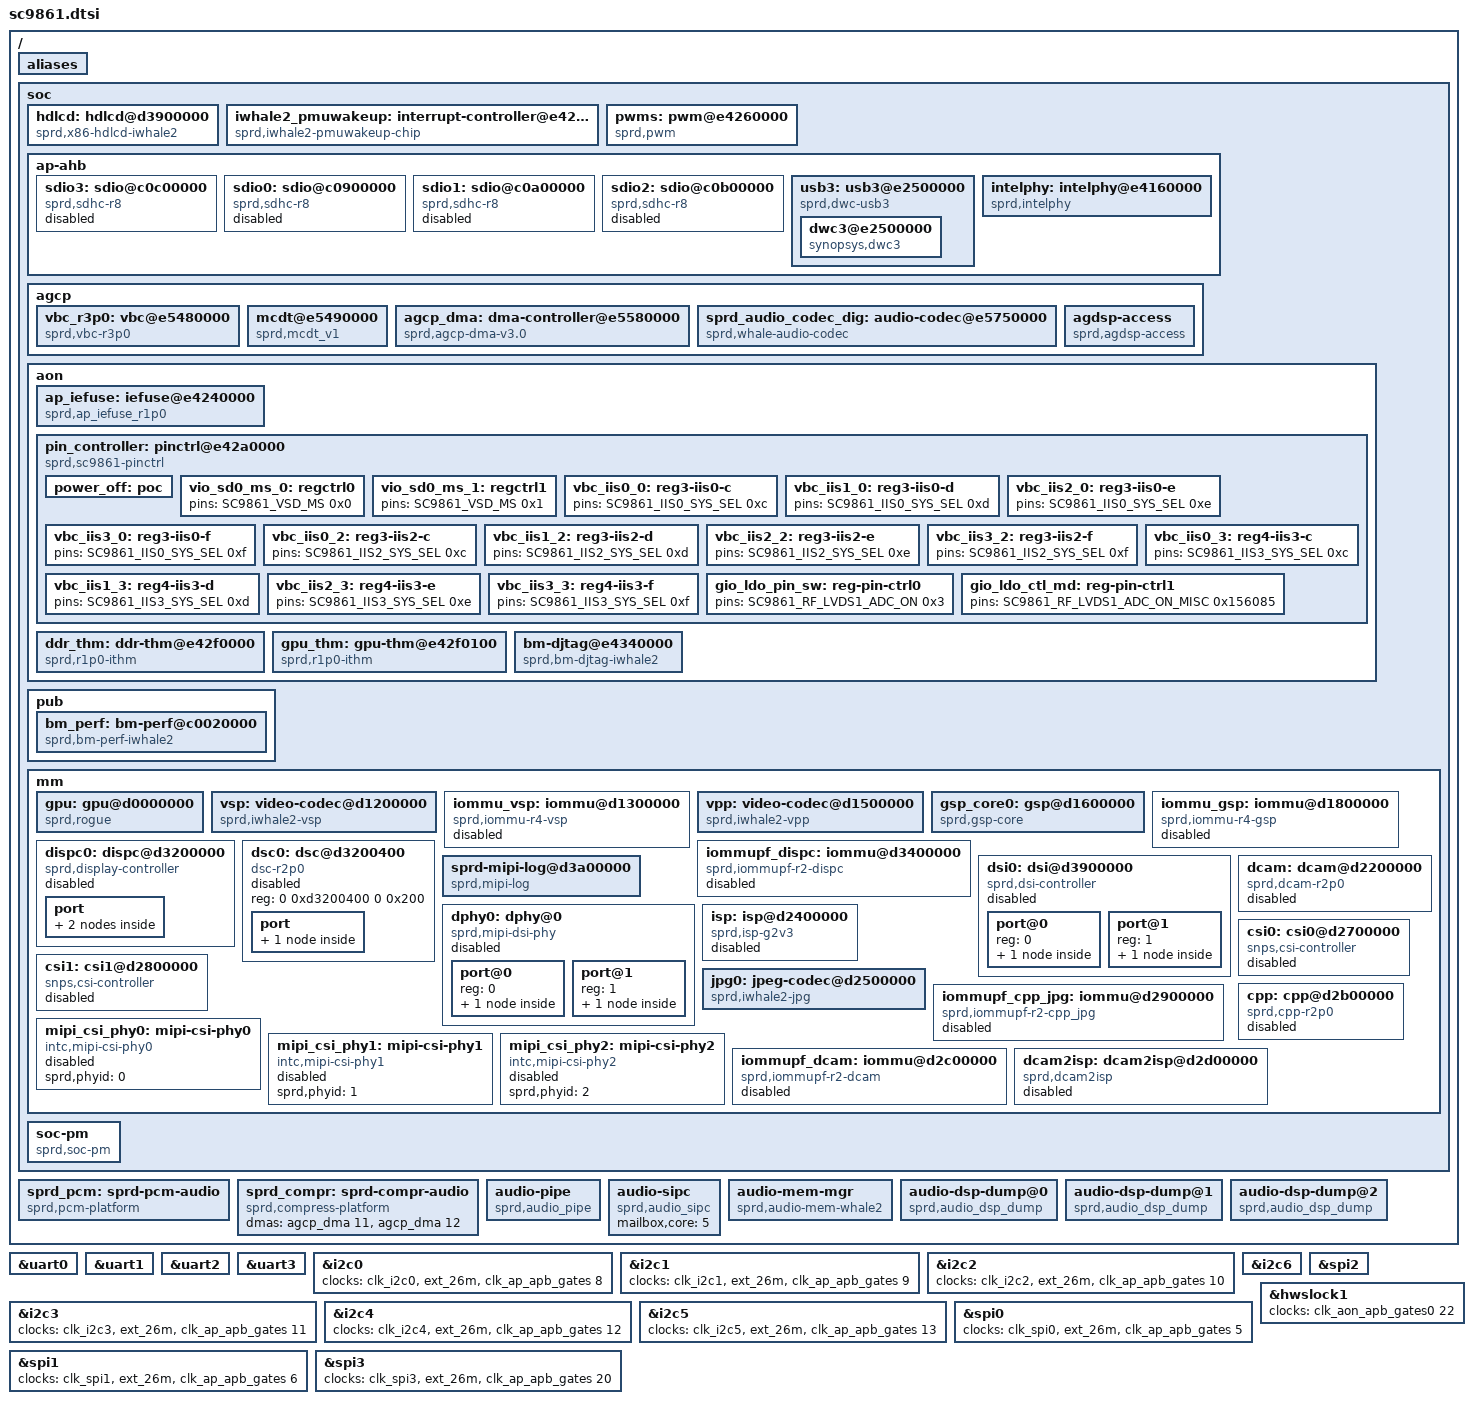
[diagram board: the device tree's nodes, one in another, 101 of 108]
/*
 * Spreadtrum iwhale2 SoC DTS file
 *
 * Copyright (C) 2015, Spreadtrum Communications Inc.
 *
 * This file is licensed under a dual GPLv2 or X11 license.
 */

#include <dt-bindings/pinctrl/sc9861_pinctrl.h>
#include "iwhale2.dtsi"
#include "sc9861-clocks.dtsi"

/{
	aliases {
		thm-sensor1 = &ddr_thm;
		thm-sensor2 = &gpu_thm;
	};

	soc {
		hdlcd:hdlcd@d3900000 {
			compatible = "sprd,x86-hdlcd-iwhale2";
			/* use dispc0 of iwhale2 */
			reg = <0x0 0xd3900000 0x0 0x1000>;
			interrupts = <DISPC0_IRQ 2>;
			clocks = <&ext_26m>;
			clock-names = "pxlclk";
			memory-region = <&fb_reserved>;
			sprd,syscon-lpc-ahb = <&lpc_ahb_controller>;
			sprd,syscon-dispc-ahb = <&dispc_ahb_controller>;
			sprd,syscon-aon-pwu-apb = <&aon_pwu_apb_controller>;
			sprd,syscon-aon-apb = <&aon_apb_controller>;
			sprd,syscon-ap-apb = <&ap_apb_controller>;
		};

		iwhale2_pmuwakeup: interrupt-controller@e42b0254 {
			compatible = "sprd,iwhale2-pmuwakeup-chip";
			interrupt-controller;
			reg = <0 0xe42b0254 0 0x10>;
		};

		pwms: pwm@e4260000 {
				#pwm-cells = <2>;
				compatible = "sprd,pwm";
				reg = <0 0xe4260000 0 0x10000>;
				clock-names = "sprd_pwm_clk_parent", "clk_pwm";
				clocks = <&ext_26m>, <&clk_pwm0>;
				status = "okay";
		};

		ap-ahb {
			sdio3: sdio@c0c00000 {
				compatible  = "sprd,sdhc-r8";
				reg = <0 0xc0c00000 0 0x100000>;
				interrupts = <SDIO3_IRQ 2>;
				clock-names = "sdio","source","enable",
					"ckg_eb","ckg_1x_eb";
				clocks = <&clk_emmc_2x>, <&clk_twpll_384m>,
					<&clk_ap_ahb_gates 10>,
					<&clk_top_cgm_reg1 9>,
					<&clk_top_cgm_reg1 8>;
				status = "disabled";
			};

			sdio0: sdio@c0900000 {
				compatible  = "sprd,sdhc-r8";
				reg = <0 0xc0900000 0 0x100000>;
				interrupts = <SDIO0_IRQ 2>;
				clock-names = "sdio", "source","enable",
					"ckg_eb", "ckg_1x_eb";
				clocks = <&clk_sdio0_2x>, <&clk_twpll_384m>,
					<&clk_ap_ahb_gates 7>,
					<&clk_top_cgm_reg1 2>,
					<&clk_top_cgm_reg1 3>;
				status = "disabled";
			};

			sdio1: sdio@c0a00000 {
				compatible  = "sprd,sdhc-r8";
				reg = <0 0xc0a00000 0 0x100000>;
				interrupts = <SDIO1_IRQ 2>;
				clock-names = "sdio", "source","enable",
					"ckg_eb","ckg_1x_eb";
				clocks = <&clk_sdio1_2x>, <&clk_twpll_384m>,
					<&clk_ap_ahb_gates 8>,
					<&clk_top_cgm_reg1 4>,
					<&clk_top_cgm_reg1 5>;
				status = "disabled";
			};

			sdio2: sdio@c0b00000 {
				compatible  = "sprd,sdhc-r8";
				reg = <0 0xc0b00000 0 0x100000>;
				interrupts = <SDIO2_IRQ 2>;
				clock-names = "sdio", "source","enable",
					"ckg_eb","ckg_1x_eb";
				clocks = <&clk_sdio2_2x>, <&clk_twpll_384m>,
					<&clk_ap_ahb_gates 9>,
					<&clk_top_cgm_reg1 6>,
					<&clk_top_cgm_reg1 7>;
				status = "disabled";
			};

			usb3: usb3@e2500000 {
				compatible = "sprd,dwc-usb3";
				reg = <0 0xe2500000 0 0x100000>;
				#address-cells = <2>;
				#size-cells = <2>;
				ranges;
				sprd,por-after-power-collapse;
				clocks = <&clk_ap_ahb_gates 2>,
					<&clk_ap_ahb_gates 3>,
					<&clk_ap_ahb_gates 4>;
				clock-names = "core_clk", "susp_clk", "ref_clk";
				sprd,syscon-ap-ahb = <&ap_ahb_controller>;

				dwc3@e2500000 {
					compatible = "synopsys,dwc3";
					reg = <0 0xe2500000 0 0xcc00>;
					interrupts = <USB3_IRQ 2>;
					interrupt-names = "irq";
					usb-phy = <&intelphy>, <&intelphy>;
					snps,usb3-u1u2-disable;
					snps,overlap_check_quirk;
					snps,ep_out_aligned_size_quirk;
					snps,disconnect_event_quirk;
				};
			};

			intelphy: intelphy@e4160000 {
				compatible = "sprd,intelphy";
				reg = <0 0xe4160000 0 0x10000>,
					<0 0xe41f0000 0 0x10000>,
					<0 0xe4103000 0 0x40>;
				reg-names = "phy_glb_regs",
						"phy_sideclk_regs",
						"phy_reset_regs";
				sprd,syscon-ap-ahb = <&ap_ahb_controller>;
				sprd,syscon-aon-com-pmu-apb = <&aon_com_pmu_apb_controller>;
				sprd,syscon-anlg-phy-g4 = <&anlg_phy_g4_controller>;
				sprd,vdd-voltage = <3300000>;
			};
		};

		agcp {
			vbc_r3p0: vbc@e5480000 {
				compatible = "sprd,vbc-r3p0";
				#sound-dai-cells = <1>;
				reg = <0 0xe5480000 0 0x1000>;
				mailbox,core = <5>;    /* AGDSP id */
				sprd,syscon-agcp-ahb = <&agcp_ahb_controller>;
				sprd,vbc-phy-offset = <0xe4000000>;
				/* iis pin map */
				pinctrl-names =
				/* iis 0 */
				"vbc_iis0_0", "vbc_iis1_0", "vbc_iis2_0", "vbc_iis3_0",
				/* iis 2 */
				"vbc_iis0_2", "vbc_iis1_2", "vbc_iis2_2", "vbc_iis3_2",
				/* iis 3 */
				"vbc_iis0_3", "vbc_iis1_3", "vbc_iis2_3", "vbc_iis3_3";
				/* sys iis 0 */
				pinctrl-0 = <&vbc_iis0_0>;
				pinctrl-1 = <&vbc_iis1_0>;
				pinctrl-2 = <&vbc_iis2_0>;
				pinctrl-3 = <&vbc_iis3_0>;
				/* sys iis 2 */
				pinctrl-4 = <&vbc_iis0_2>;
				pinctrl-5 = <&vbc_iis1_2>;
				pinctrl-6 = <&vbc_iis2_2>;
				pinctrl-7 = <&vbc_iis3_2>;
				/* sys iis 3 */
				pinctrl-8 = <&vbc_iis0_3>;
				pinctrl-9 = <&vbc_iis1_3>;
				pinctrl-10 = <&vbc_iis2_3>;
				pinctrl-11 = <&vbc_iis3_3>;
				sprd,need-aud-top-clk;
			};

			mcdt@e5490000 {
				compatible = "sprd,mcdt_v1";
				reg = <0 0xe5490000 0 0x170>;
				interrupts = <AGCP_MCDT_IRQ 2>;
				sprd,ap-addr-offset = <0xe4000000>;
			};

			agcp_dma: dma-controller@e5580000 {
				compatible = "sprd,agcp-dma-v3.0";
				reg = <0 0xe5580000 0 0x10000>;
				#dma-cells = <1>;
				#dma-channels = <32>;
				sprd,full-type-offset = <0>;
				sprd,syscon-dma-glb = <&agcp_ahb_controller>;
				clock-names = "enable", "ashb_eb";
				clocks = <&clk_agcp_ahb_gates 6>, <&clk_agcp_ahb_gates 17>;
			};

			sprd_audio_codec_dig: audio-codec@e5750000 {
				compatible = "sprd,whale-audio-codec";
				reg = <0 0xe5750000 0 0x1000>;
				sprd,syscon-agcp-ahb = <&agcp_ahb_controller>;
			};

			agdsp-access {
				compatible = "sprd,agdsp-access";
				sprd,syscon-agcp-ahb = <&aon_apb_controller>;
				sprd,syscon-pmu-apb = <&aon_pwu_apb_controller>;
				sprd,dst = <5>;
				sprd,channel = <130>;
				sprd,sipc-name = "sipc0";
				mailbox,core = <5>; /* AGDSP id */
				sprd,ddr-addr-offset = <0x80000000>;
			};
		};

		aon {
			ap_iefuse: iefuse@e4240000 {
				compatible = "sprd,ap_iefuse_r1p0";
				sprd,syscon-enable = <&aon_apb_controller>;
				reg = <0 0xe4240000 0 0x10000>;
				clock-names = "enable";
				clocks = <&clk_aon_apb_gates0 13>;
				sprd,block-num = <64>;
				sprd,block-width = <32>;
				hwlocks = <&hwslock1 8>;
				hwlock-names = "ap_efuse";
			};

			pin_controller: pinctrl@e42a0000 {
				compatible = "sprd,sc9861-pinctrl";
				reg = <0 0xe42a0000 0 0x10000>;
			};

			ddr_thm: ddr-thm@e42f0000 {
				compatible = "sprd,r1p0-ithm";
				sprd,syscon-enable = <&aon_apb_controller>;
				reg = <0 0xe42f0000 0 0x100>;
				clock-names = "enable";
				clocks = <&clk_aon_apb_gates1 1>;
				#thermal-sensor-cells = <1>;
				power-down = <1>;
				otp-temp = <120000>;
				algor_ver = <0>;
				cal_k = <1455>;
				cal_b = <67200>;
				cal_efuse_blk = <7>;
				cal_efuse_bit = <13>;
				ratio_off_bit = <6>;
				ratio_sign_bit = <12>;
			};

			gpu_thm: gpu-thm@e42f0100 {
				compatible = "sprd,r1p0-ithm";
				sprd,syscon-enable = <&aon_apb_controller>;
				reg = <0 0xe42f0100 0 0x100>;
				clock-names = "enable";
				clocks = <&clk_aon_apb_gates1 1>;
				#thermal-sensor-cells = <1>;
				power-down = <1>;
				otp-temp = <120000>;
				algor_ver = <0>;
				cal_k = <1455>;
				cal_b = <67200>;
				cal_efuse_blk = <8>;
				cal_efuse_bit = <13>;
				ratio_off_bit = <6>;
				ratio_sign_bit = <12>;
			};

			bm-djtag@e4340000 {
				compatible  = "sprd,bm-djtag-iwhale2";
				reg = <0 0xe4340000 0 0x10000>;
				interrupts = <DJTAG_IRQ 2>;
				sprd,syscon-aon-glb = <&aon_apb_controller>;
				sprd,syscon-ap-glb = <&ap_ahb_controller>;
				hwlocks = <&hwslock1 10>;
				hwlock-names = "djtag";
			};
		};

		pub {
			bm_perf: bm-perf@c0020000 {
				compatible = "sprd,bm-perf-iwhale2";
				reg =	<0 0xc0020000 0 0x60000>,
					<0 0xc0820000 0 0x60000>,
					<0 0xe44D0000 0 0x10000>,
					<0 0xc0010000 0 0x4>,
					<0 0xc0810000 0 0x4>;
				reg-names = "pub0","pub1","timer",
						"pub0_glb","pub1_glb";
				interrupts = <PUB0_AXI_BM_IRQ 2>,
						<PUB1_AXI_BM_IRQ 2>;
				sprd,syscon-aon-glb =  <&aon_apb_controller>;
			};
		};

		mm {
			gpu: gpu@d0000000 {
				compatible = "sprd,rogue";
				reg = <0 0xd0000000 0 0x100000>;
				sprd,syscon-aon-pwu-apb = <&aon_pwu_apb_controller>;
				interrupts = <GPU_IRQ 2>;

				clocks = <&clk_aon_apb_gates0 27>,
					<&clk_gpu_core>,<&clk_gpu_mem>,
					<&clk_gpu_sys>,<&clk_twpll_384m>,
					<&clk_twpll_512m>,<&clk_gpll>;

				operating-points = <
					/* kHz    uV */
					384000    840000
					512000    1050000
					583000    1050000
					>;

				sprd,dvfs-lists = <
					/* kHz  uV     idx div */
					384000 840000   4   1
					512000 1050000  5   1
					583000 1050000  6   1
					>;

				sprd,dvfs-default = <2>;
				sprd,dfs-scene-max = <2>;
				sprd,dfs-scene-extreme = <1>;
			};

			vsp: video-codec@d1200000{
				compatible = "sprd,iwhale2-vsp";
				reg = <0 0xd1200000 0 0x20000>;
				interrupts = <VSP_IRQ 2>;
				sprd,syscon-pmu-apb = <&aon_pwu_apb_controller>;
				sprd,syscon-com-pmu-apb = <&aon_com_pmu_apb_controller>;
				sprd,syscon-aon-apb = <&aon_apb_controller>;
				sprd,syscon-mm-ahb = <&vsp_sys_ahb_controller>;
				clock-names = "clk_mm_eb",
						"clk_axi_gate_vsp",
						"clk_vsp_ahb_mmu_eb",
						"clk_vsp_ckg",
						"clk_ahb_gate_vsp_eb",
						"clk_ahb_vsp",
						"ahb_parent_clk",
						"ahb_parent_df_clk",
						"clk_vsp";
				clocks = <&clk_aon_apb_gates1 28>,
					<&clk_vsp_ahb_gates 10>,
					<&clk_vsp_ahb_gates 2>,
					<&clk_vsp_ahb_gates 1>,
					<&clk_vsp_ahb_gates 0>,
					<&clk_vsp_ahb>,
					<&clk_twpll_153m6>,
					<&clk_twpll_96m>,
					<&clk_vsp>;
				iommus = <&iommu_vsp>;
				status = "okay";
			};

			iommu_vsp: iommu@d1300000 {
				compatible = "sprd,iommu-r4-vsp";
				reg = <0 0xd1300000 0 0x20000>,
					<0 0xd1320000 0 0x2000>,
					<0 0xe0000000 0 0x8000000>;
				reg_name = "pgt","ctrl_reg","iova pool";
				clock-names = "clk_vsp_ahb_mmu_eb",
						"clk_vsp_apb_gate";
				clocks = <&clk_vsp_ahb_gates 2>,
						<&clk_aon_apb_gates1 28>;

				sprd,reserved-fault-page = <0xffff0000>;
				sprd,reserved-rr-page = <0x5f700000>;
				page-table-offset = <1>;
				page-table-size = <256>;
				status = "disable";
				#iommu-cells = <0>;
			};

			vpp: video-codec@d1500000{
				compatible = "sprd,iwhale2-vpp";
				reg = <0 0xd1500000 0 0xc000>;
				interrupts = <VPP_DEINT_IRQ 2>;
				sprd,syscon-aon-apb = <&aon_apb_controller>;
				sprd,syscon-mm-ahb = <&vsp_sys_ahb_controller>;
				clock-names = "clk_mm_eb",
					"clk_axi_gate_vsp",
					"clk_vsp_ckg",
					"clk_ahb_gate_vsp_eb",
					"clk_ahb_vsp",
					"clk_vsp";
				clocks = <&clk_aon_apb_gates1 28>,
					<&clk_vsp_ahb_gates 10>,
					<&clk_vsp_ahb_gates 2>,
					<&clk_vsp_ahb_gates 4>,
					<&clk_vsp_ahb>,
					<&clk_vpp>;
				iommus = <&iommu_vsp>;
				status = "okay";
			};

			gsp_core0: gsp@d1600000 {
				compatible = "sprd,gsp-core";
				reg = <0 0xd1600000 0 0x1000>,
					<0 0xd1100000 0 0x1000>,
					<0 0xd1000000 0 0x1000>;
				reg-names = "gsp_ctl_reg_base",
						"vsp_sys_regmap",
						"vsp_clk_regmap";
				core-id = <0>;
				kcfg-num = <16>;
				interrupts = <GSP0_IRQ 2>;
				iommus = <&iommu_gsp>;
				sprd,syscon-pmu-apb = <&aon_pwu_apb_controller>;
				sprd,syscon-aon-apb = <&aon_apb_controller>;

				clock-names = "clk_gsp0","clk_gsp_parent",
					"clk_gsp_ahb_vsp",
					"clk_gsp_ahb_vsp_parent",
					"clk_gsp_mtx","clk_gsp_mtx_parent",
					"clk_vsys_mtx","clk_vsys_mtx_parent",
					"clk_aon_vsp_eb",
					"clk_gsp_emc_eb",
					"clk_vsp_ahb_ckg_eb",
					"clk_vsys_mtx_eb",
					"clk_gsp0_eb",
					"clk_gsp_mmu_eb",
					"clk_gsp_mtx_eb";
				clocks = <&clk_gsp0>,<&clk_twpll_512m>,
					<&clk_vsp_ahb>,<&clk_twpll_153m6>,
					<&clk_gsp_mtx>,<&clk_twpll_512m>,
					<&clk_vsys_mtx>,<&clk_twpll_512m>,
					<&clk_aon_apb_gates1 28>,
					<&clk_aon_apb_gates1 13>,
					<&clk_vsp_ahb_gates 1>,
					<&clk_vsp_ahb_gates 10>,
					<&clk_vsp_ahb_gates 5>,
					<&clk_vsp_ahb_gates 7>,
					<&clk_vsp_ahb_gates 9>;
			};

			iommu_gsp: iommu@d1800000 {
				compatible = "sprd,iommu-r4-gsp";
				reg = <0 0xd1800000 0 0x40000>,
				<0 0xd1840000 0 0x2000>,
				<0 0xc0000000 0 0xc800000>;
				reg_name = "pgt","ctrl_reg","iova pool";
				clock-names = "clk_dispc_gsp0_mmu_ahb_eb",
						"clk_vsp_eb";
				clocks = <&clk_vsp_ahb_gates 7>,
						<&clk_aon_apb_gates1 28>;
				sprd,reserved-fault-page = <0xffff0000>;
				page-table-offset = <0>;
				page-table-size = <256>;
				status = "disable";
				#iommu-cells = <0>;
			};

			dispc0: dispc@d3200000 {
				compatible = "sprd,display-controller";
				reg = <0 0xd3200000 0 0x1000>;
				dev-id = <0>;
				sprd,dpi_clk_div = <1>;
				interrupts = <DISPC0_IRQ 2>;
				clock-src = <512000000 256000000 256000000>;
				clock-names =   "clk_dispc_core_parent",
						"clk_dispc_dpi_parent",
						"clk_dispc_core",
						"clk_dispc_dpi",
						"clk_dispc_ahb_eb",
						"clk_dispc_mmu_ahb_eb",
						"clk_dispc_ckg_ahb_eb",
						"clk_dispc_mtx_ahb_eb",
						"clk_disp_emc_apb_eb",
						"clk_disp_apb_eb";

				clocks =	<&clk_twpll_512m>,
						<&clk_twpll_256m>,
						<&clk_dispc0>,
						<&clk_dispc0_dpi>,
						<&clk_dahb_gates 0>,
						<&clk_dahb_gates 2>,
						<&clk_dahb_gates 9>,
						<&clk_dahb_gates 16>,
						<&clk_aon_apb_gates1 11>,
						<&clk_aon_apb_gates1 30>;

				status = "disabled";

				sprd,ip = "dispc-r8p0";
				sprd,soc = "iwhale2";

				/* output port */
				port {
					#address-cells = <1>;
					#size-cells = <0>;

					dispc0_out: endpoint@0 {
						reg = <0>;
						remote-endpoint = <&dsi0_in>;
					};

					dispc0_dsc0: endpoint@1 {
						reg = <1>;
						remote-endpoint = <&dsc0_dispc0>;
					};
				};
			};

			dsc0: dsc@d3200400 {
				compatible  = "dsc-r2p0";
				reg = <0 0xd3200400 0 0x200>;
				status = "disable";

				/* input port */
				port {
					dsc0_dispc0: endpoint {
						remote-endpoint = <&dispc0_dsc0>;
					};
				};
			};

			iommupf_dispc: iommu@d3400000 {
				compatible = "sprd,iommupf-r2-dispc";
				reg = <0 0xd3400000 0 0x2000>,
					<0 0xd3402000 0 0x2000>,
					<0 0 0 0>,
					<0 0x30000000 0 0x10000000>;
				reg_name = "pgt",
					"ctrl_reg",
					"iova fullmode pool",
					"iova pf pool";
				clock-names = "clk_dispc_mmu_ahb_eb",
					"clk_dcam_eb";
				clocks = <&clk_dahb_gates 2>,
						<&clk_aon_apb_gates1 29>;
				fullmode-en = <0>;
				total-ch-num = <6>;
				pf-ch-write-start = <0>;
				pf-ch-write-end = <0>;
				pf-ch-read-start = <0>;
				pf-ch-read-end = <5>;
				fullmode-ch-write = <0>;
				fullmode-ch-read = <0>;
				page-table-offset = <4>;
				page-table-size = <100>;
				status = "disable";
				#iommu-cells = <0>;
			};

			dsi0: dsi@d3900000 {
				compatible = "sprd,dsi-controller";
				#address-cells = <1>;
				#size-cells = <0>;
				dev-id = <0>;
				reg = <0 0xd3900000 0 0x1000>;
				interrupts = <DSI0_IRQ 2>;
				clock-names =   "clk_dphy0_ckg_eb",
						"clk_disp_ckg_ahb_eb",
						"clk_dsi0_ahb_eb",
						"clk_disp_apb_eb";

				clocks =	<&clk_dckg_gates 0>,
						<&clk_dahb_gates 9>,
						<&clk_dahb_gates 7>,
						<&clk_aon_apb_gates1 30>;
				status = "disabled";

				sprd,ip = "synps,dwc-mipi-dsi-host";
				sprd,soc = "iwhale2";

				/* output port */
				port@0 {
					reg = <0>;
					dsi0_out: endpoint {
						remote-endpoint = <&dphy0_in>;
					};
				};

				/* input port */
				port@1 {
					reg = <1>;
					dsi0_in: endpoint {
						remote-endpoint = <&dispc0_out>;
					};
				};
			};

			sprd-mipi-log@d3a00000 {
				compatible = "sprd,mipi-log";
				reg = <0 0xd3a00000 0 0x1000>,
				    <0 0x404f0000 0 0x1000>;
				max-lanes = <4>;
				phy-freq = <1000000>;
			};

			dphy0: dphy@0 {
				compatible = "sprd,mipi-dsi-phy";
				#address-cells = <1>;
				#size-cells = <0>;
				reg = <0 0xd3900000 0 0x1000>,
				  <0 0xe41b0000 0 0x1000>;
				status = "disabled";

				sprd,ip = "intel,ip733mdsitop";
				sprd,soc = "iwhale2";

				/* output port */
				port@0 {
					reg = <0>;
					dphy0_out: endpoint {
					};
				};

				/* input port*/
				port@1 {
					reg = <1>;
					dphy0_in: endpoint {
						remote-endpoint = <&dsi0_out>;
					};
				};
			};

			dcam: dcam@d2200000 {
				compatible = "sprd,dcam-r2p0";
				reg = <0 0xd2200000 0 0x100000
					0 0xd2300000 0 0x100000>;
				interrupts = <DCAM0_IRQ 2>,
					<DCAM1_IRQ 2>;
				clock-names = "clk_cam_eb",
					"cam_ckg_eb","cam_mtx_eb",
					"clk_ahb_cam", "clk_ahb_cam_parent",
					"clk_dcam0","clk_dcam0_parent",
					"clk_dcam1","clk_dcam1_parent",
					"clk_dcam0_if","clk_dcam0_if_parent",
					"dcam0_eb","dcam0_axi_eb",
					"dcam1_eb","dcam1_axi_eb",
					"dcam0_if_eb","d0_if_axi_eb",
					"d0if_in_d_eb","d1if_in_d_eb";
				clocks = <&clk_aon_apb_gates1 29>,
					<&clk_dahb_gates 9>,<&clk_cam_ahb_gates 23>,
					<&clk_cam_ahb>,<&clk_twpll_153m6>,
					<&clk_dcam0>,<&clk_twpll_384m>,
					<&clk_dcam1>,<&clk_twpll_384m>,
					<&clk_dcam0_if>,<&clk_twpll_512m>,
					<&clk_cam_ahb_gates 0>,
					<&clk_cam_ckg_gates 4>,
					<&clk_cam_ahb_gates 1>,
					<&clk_cam_ckg_gates 5>,
					<&clk_cam_ahb_gates 20>,
					<&clk_cam_ckg_gates 14>,
					<&clk_module_gates 0>,
					<&clk_module_gates 1>;
				sprd,syscon-cam-ahb = <&lpc_ahb_controller>;
				sprd,syscon-pmu-apb = <&aon_pwu_apb_controller>;
				status = "disable";
			};

			isp: isp@d2400000 {
				compatible = "sprd,isp-g2v3";
				reg = <0 0xd2400000 0 0x100000>;
				interrupts = <ISP_CH0_IRQ 2>;
				clock-names = "clk_isp_mclk","clk_isp_mclk_parent",
					"clk_isp_pclk","clk_isp_pclk_parent",
					"clk_isp_iclk","clk_isp_iclk_parent",
					"clk_isp_lclk","clk_isp_lclk_parent",
					"clk_isp0","clk_isp0_parent",
					"clk_isp1","clk_isp1_parent",
					"clk_isp2","clk_isp2_parent",
					"isp0_eb","isp0_axi_eb",
					"isp1_eb","isp1_axi_eb",
					"isp2_eb","isp2_axi_eb",
					"isp_mclk_eb","isp_pclk_eb",
					"isp_iclk_eb","isp_lclk_eb",
					"isp_i2d_eb","i0_in_isp_eb",
					"i1_in_isp_eb","i2_in_isp_eb";
				clocks = <&clk_isp_mck>,<&clk_twpll_384m>,
					<&clk_isp_pck>,<&clk_twpll_76m8>,
					<&clk_isp_ick>,<&clk_twpll_512m>,
					<&clk_isp_lck>,<&clk_twpll_384m>,
					<&clk_ci_isp0>,<&clk_twpll_512m>,
					<&clk_ci_isp1>,<&clk_twpll_512m>,
					<&clk_ci_isp2>,<&clk_twpll_384m>,
					<&clk_cam_ahb_gates 2>,
					<&clk_cam_ckg_gates 10>,
					<&clk_cam_ahb_gates 9>,
					<&clk_cam_ckg_gates 11>,
					<&clk_cam_ahb_gates 12>,
					<&clk_cam_ckg_gates 12>,
					<&clk_cam_ahb_gates 17>,
					<&clk_cam_ahb_gates 18>,
					<&clk_cam_ahb_gates 16>,
					<&clk_cam_ahb_gates 15>,
					<&clk_cam_ahb_gates 19>,
					<&clk_module_gates 7>,
					<&clk_module_gates 8>,
					<&clk_module_gates 9>;
				sprd,syscon-cam-ahb = <&lpc_ahb_controller>;
				status = "disable";
			};

			jpg0: jpeg-codec@d2500000{
				compatible = "sprd,iwhale2-jpg";
				reg = <0 0xd2500000 0 0x100000>;
				interrupts = <JPG0_IRQ 2>;
				sprd,syscon-aon-apb = <&aon_apb_controller>;
				sprd,syscon-mm-ahb = <&lpc_ahb_controller>;
				clock-names = "clk_mm_eb",
					"clk_axi_gate_jpg",
					"clk_ahb_gate_jpg_eb",
					"clk_ahb_cam",
					"clk_jpg";
				clocks = <&clk_aon_apb_gates1 29>,
					<&clk_cam_ckg_gates 8>,
					<&clk_cam_ahb_gates 5>,
					<&clk_cam_ahb>,
					<&clk_jpg0>;
				/*iommus = <&iommupf_cpp_jpg>;*/
				status = "okay";
			};

			csi0: csi0@d2700000 {
				compatible = "snps,csi-controller";
				reg = <0 0xd2700000 0 0x100000>;
				interrupts = <CSI0_IRQ 2>;
				clock-names = "clk_cphy_gate","clk_mipi_gate",
					"clk_csi_eb","clk_mipi_csi_eb";
				clocks = <&clk_cam_ckg_gates 0>,<&clk_cam_ckg_gates 1>,
					   <&clk_cam_ahb_gates 3>,<&clk_mipi_csi0_gate 16>;
				sprd,ip-version = <0x3131312a>;
				sprd,cam-ahb-syscon = <&lpc_ahb_controller>;
				sprd,aon-apb-syscon = <&aon_apb_controller>;
				sprd,anlg-phy-g8-syscon = <&anlg_phy_g8_controller>;
				status = "disable";
			};

			csi1: csi1@d2800000 {
				compatible = "snps,csi-controller";
				reg = <0 0xd2800000 0 0x100000>;
				interrupts = <CSI1_IRQ 2>;
				clock-names = "clk_cphy_gate","clk_mipi_gate",
					"clk_csi_eb","clk_mipi_csi_eb";
				clocks = <&clk_cam_ckg_gates 2>,<&clk_cam_ckg_gates 3>,
					   <&clk_cam_ahb_gates 4>,<&clk_mipi_csi1_gate 16>;
				sprd,ip-version = <0x3131312a>;
				sprd,cam-ahb-syscon = <&lpc_ahb_controller>;
				sprd,aon-apb-syscon = <&aon_apb_controller>;
				sprd,anlg-phy-g8-syscon = <&anlg_phy_g8_controller>;
				status = "disable";
			};

			iommupf_cpp_jpg: iommu@d2900000 {
				compatible = "sprd,iommupf-r2-cpp_jpg";
				reg = <0 0xd2900000 0 0x2000>,
					<0 0xd2902000 0 0x2000>,
					<0 0x40000000 0 0x8000000>,
					<0 0x50000000 0 0x20000000>;
				reg_name = "pgt",
					"ctrl_reg",
					"iova fullmode pool",
					"iova pf pool";
				clock-names = "clk_cam_mmupf_ahb_eb",
					"clk_cam_apb_eb";
				clocks = <&clk_cam_ahb_gates 8>,
						<&clk_aon_apb_gates1 29>;
				fullmode-en = <1>;
				total-ch-num = <14>;
				pf-ch-write-start = <0>;
				pf-ch-write-end = <6>;
				pf-ch-read-start = <7>;
				pf-ch-read-end = <13>;
				fullmode-ch-write = <0>;
				fullmode-ch-read = <7>;
				page-table-offset = <3>;
				page-table-size = <100>;
				status = "disable";
				#iommu-cells = <0>;
			};

			mipi_csi_phy0: mipi-csi-phy0 {
				compatible = "intc,mipi-csi-phy0";
				sprd,phyid = <0>;
				#phy-cells = <1>;
				status = "disable";
			};

			mipi_csi_phy1: mipi-csi-phy1 {
				compatible = "intc,mipi-csi-phy1";
				sprd,phyid = <1>;
				#phy-cells = <1>;
				status = "disable";
			};

			mipi_csi_phy2: mipi-csi-phy2 {
				compatible = "intc,mipi-csi-phy2";
				sprd,phyid = <2>;
				#phy-cells = <1>;
				status = "disable";
			};

			cpp: cpp@d2b00000 {
				compatible = "sprd,cpp-r2p0";
				reg = <0 0xd2b00000 0 0x100000>;
				interrupts = <CPP_IRQ 2>;
				clock-names = "clk_cpp","clk_cpp_parent",
					"cpp_eb",
					"cpp_axi_eb";
				clocks = <&clk_cpp>,<&clk_twpll_384m>,
					<&clk_cam_ahb_gates 10>,
					<&clk_cam_ckg_gates 13>;
				sprd,syscon-cam-ahb = <&lpc_ahb_controller>;
				sprd,syscon-pmu-apb = <&aon_pwu_apb_controller>;
				status = "disable";
			};

			iommupf_dcam: iommu@d2c00000 {
				compatible = "sprd,iommupf-r2-dcam";
				reg = <0 0xd2c00000 0 0x2000>,
					<0 0xd2c02000 0 0x2000>,
					<0 0x90000000 0 0x8a00000>,
					<0 0xa0000000 0 0x40000000>;
				reg_name = "pgt",
					"ctrl_reg",
					"iova fullmode pool",
					"iova pf pool";
				clock-names = "clk_cam_mmupf_ahb_eb",
					"clk_cam_apb_eb";
				clocks = <&clk_cam_ahb_gates 11>,
						<&clk_aon_apb_gates1 29>;
				fullmode-en = <1>;
				total-ch-num = <28>;
				pf-ch-write-start = <0>;
				pf-ch-write-end = <24>;
				pf-ch-read-start = <25>;
				pf-ch-read-end = <27>;
				fullmode-ch-write = <0>;
				fullmode-ch-read = <25>;
				page-table-offset = <2>;
				page-table-size = <100>;
				status = "disable";
				#iommu-cells = <0>;
			};

			dcam2isp: dcam2isp@d2d00000 {
				compatible = "sprd,dcam2isp";
				reg = <0 0xd2d00000 0 0x100000>;
				interrupts = <DCAM2ISP_IF_IRQ 2>;
				clock-names = "dcam2isp_if_eb","d2i_if_axi_gate",
					"d0if_in_d2i_eb","d1if_in_d2i_eb",
					"i0_in_d2i_eb","i1_in_d2i_eb",
					"i2_in_d2i_eb";
				clocks = <&clk_cam_ahb_gates 13>,
					<&clk_cam_ckg_gates 15>,
					<&clk_module_gates 2>,
					<&clk_module_gates 3>,
					<&clk_module_gates 4>,
					<&clk_module_gates 5>,
					<&clk_module_gates 6>;
				sprd,syscon-cam-ahb = <&lpc_ahb_controller>;
				status = "disable";
			};
		};

		soc-pm {
			compatible = "sprd,soc-pm";
			sprd,sys-bia-intc = <&pic>;
			sprd,sys-ap-apb = <&ap_apb_controller>;
			sprd,sys-ap-ahb = <&ap_ahb_controller>;
			sprd,sys-aon-apb = <&aon_apb_controller>;
			sprd,sys-pub0-apb = <&pub0_apb_controller>;
			sprd,sys-aon-pwu-apb = <&aon_pwu_apb_controller>;
			sprd,sys-aon-lpc-apb = <&aon_lpc_apb_controller>;
			sprd,sys-aon-common-apb = <&aon_common_apb_controller>;
			sprd,sys-aon-com-pmu-apb = <&aon_com_pmu_apb_controller>;
			sprd,sys-aon-intc0 = <&aon_intc0_controller>;
			sprd,sys-aon-intc1 = <&aon_intc1_controller>;
			sprd,sys-aon-intc2 = <&aon_intc2_controller>;
			sprd,sys-aon-intc3 = <&aon_intc3_controller>;

			sprd,deep-ap-clk0 = <&clk_ap_apb &clk_uart0 &clk_uart1
				&clk_uart2 &clk_uart3 &clk_uart4 &clk_i2c0
				&clk_i2c1 &clk_i2c2 &clk_i2c3 &clk_i2c4
				&clk_i2c5 &clk_spi0 &clk_spi1 &clk_spi3
				&clk_efs &clk_ce0 &clk_ce1 &clk_ap_axi>;
			sprd,deep-ap-clk1 = <&clk_usb3_ref>;
			sprd,deep-ap-clk2 = <&clk_iis0 &clk_iis1 &clk_iis2
				&clk_iis3>;
			sprd,deep-ap-clkp = <&ext_26m &ext_32k
				&clk_twpll_153m6>;
		};
	};

	sprd_pcm: sprd-pcm-audio {
		compatible = "sprd,pcm-platform";
		#sound-dai-cells = <0>;
		/* agcp dma_ap */
		dmas = <&agcp_dma 1 &agcp_dma 2
			&agcp_dma 3 &agcp_dma 4
			&agcp_dma 5 &agcp_dma 6
			&agcp_dma 7 &agcp_dma 8
			&agcp_dma 9 &agcp_dma 10>;
		dma-names = "normal_p_l", "normal_p_r",
			"normal_c_l", "normal_c_r",
			"voice_c","fast_p",
			"loop_c", "loop_p",
			"voip_c", "voip_p";
	};

	sprd_compr: sprd-compr-audio {
		compatible = "sprd,compress-platform";
		#sound-dai-cells = <1>;
		dmas = <&agcp_dma 11 &agcp_dma 12>;
		dma-names = "compr_dma_stage0", "compr_dma_stage1";
	};

	audio-pipe {
		compatible = "sprd,audio_pipe";
		sprd,name = "audio_pipe";
		sprd,dst = /bits/ 8 <1>; /* AGDSP */
		sprd,devicesnr = /bits/ 8  <1>; /* AGDSP id */
		mailbox,core = <5>; /* AGDSP id */
	};

	audio-sipc{
		compatible = "sprd,audio_sipc";
		mailbox,core = <5>;  /* AGDSP id */
	};

	audio-mem-mgr {
		compatible = "sprd,audio-mem-whale2";
		sprd,ddr32-dma = <0x283000>; /* size of mem used for dma */
		/* size of mem used for dsp mem dump */
		sprd,ddr32-dspmemdump = <0x7d000>;
		sprd,iram-ap-base =  <0xe6012000>;
		sprd,iram-dsp-base = <0x30800000>;
		sprd,cmdaddr = <0xe6012000 0x1000>;/* for cmd para addr */
		sprd,smsg-addr = <0xe6013000 0xa10>;  /* smsg  addr */
		sprd,shmaddr-aud-str = <0xe6013a10 0x340>;
		sprd,shmaddr-dsp-vbc = <0xe6013d50 0x113c>;
		/* nxp size 0x30c, cvs size 0x33c shared with nxp */
		sprd,shmaddr-nxp = <0xe6014e8c 0x400>;
		sprd,shmaddr-reg-dump = <0xe601528c 0x400>;
		/* 0xe601568c - 0xe6015690, size 4bytes.
		 * holes for 8bytes align
		 */
		/* offload/(test dsplog) 0xe6015690 - 0xe601da90,
		 * size 0x8400
		 */
		sprd,offload-addr = <0xe6015690 0x8400>; /* offload */
		sprd,dsplog = <0xe6015690 0x2800>; /* dsp log */
		/*
		 * normal capture linklist node1
		 * 0xe601da90 - 0xe601dc90 size 0x200 (0.5k)
		 * base address must 8 bytes aligned
		 */
		sprd,normal-captue-linklilst-node1 =<0xe601da90 0x200>;
		/*
		 * normal capture linklist node2
		 * 0xe601dc90 - 0xe601de90 size 0x200
		 * base address must 8 bytes aligned
		 */
		sprd,normal-captue-linklilst-node2 =<0xe601dc90 0x200>;
		/* reserved holes 0xe601de90 0xe601e000 size 0x170(368 byts)*/
		/*
		 * normal capture data 0xe601e000 - 0xe601fc90 size
		 * 0x1e00 (960*4*2), base address must pagesize
		 * aligned(for arm64, x86 page size is 4k)
		 */
		sprd,normal-captue-data =<0xe601e000 0x1e00>;
		/* reseved 0xe601fe00 - 0xe6021000 size 0x1200(4.5k) */
		/*
		 * dsp use 0xe6021000 - 0xe6022000 size 0x1000 (4k),
		 *dsp addr 0x3080f000-3080ffff, last 4k.
		 */
		sprd,dma-offset = <0x80000000>; /* dma addr offset */
	};

	audio-dsp-dump@0 {/* audio dsp log */
		compatible = "sprd,audio_dsp_dump";
		sprd-name = "audio_dsp_log";
		sprd-dump-content = "log";
		sprd-usemem-type =<0x4>;
		sprd-dst = /bits/ 8 <1>; /* AGDSP */
		sprd-channel =/bits/ 8 <4>;
		sprd-rxblocknum=<0x8>;
		sprd-rxblocksize=<0x2000>;
	};

	audio-dsp-dump@1 {/* audio dsp pcm */
		compatible = "sprd,audio_dsp_dump";
		sprd-name = "audio_dsp_pcm";
		sprd-dump-content = "pcm";
		sprd-usemem-type =<0x4>;
		sprd-dst = /bits/ 8 <1>; /* AGDSP */
		sprd-channel =/bits/ 8 <3>;
		sprd-rxblocknum=<0x8>;
		sprd-rxblocksize=<0x2000>;
	};

	audio-dsp-dump@2 {/* audio dsp log */
		compatible = "sprd,audio_dsp_dump";
		sprd-name = "audio_dsp_mem";
		sprd-dump-content = "memory";
		sprd-usemem-type =<0x8>;
		sprd-usemem-bytes =<0x7d000>;
		sprd-dst = /bits/ 8 <1>; /* AGDSP */
		sprd-channel =/bits/ 8 <5>;
		/* for cmd para addr */
		sprd,dspdumpmem = <0xe5000000 0x50000
				   0x401b0000 0x2000
				   0xe6027000 0x1000>;
	};
};

&uart0 {
	clocks = <&clk_uart0>, <&ext_26m>,
		<&clk_ap_apb_gates 14>;
};

&uart1 {
	clocks = <&clk_uart1>, <&ext_26m>,
		<&clk_ap_apb_gates 15>;
};

&uart2 {
	clocks = <&clk_uart2>, <&ext_26m>,
		<&clk_ap_apb_gates 16>;
};

&uart3 {
	clocks = <&clk_uart3>, <&ext_26m>,
		<&clk_ap_apb_gates 17>;
};

&i2c0 {
	clocks = <&clk_i2c0>, <&ext_26m>,
		<&clk_ap_apb_gates 8>;
};

&i2c1 {
	clocks = <&clk_i2c1>, <&ext_26m>,
		<&clk_ap_apb_gates 9>;
};

&i2c2 {
	clocks = <&clk_i2c2>, <&ext_26m>,
		<&clk_ap_apb_gates 10>;
};

&i2c3 {
	clocks = <&clk_i2c3>, <&ext_26m>,
		<&clk_ap_apb_gates 11>;
};

&i2c4 {
	clocks = <&clk_i2c4>, <&ext_26m>,
		<&clk_ap_apb_gates 12>;
};

&i2c5 {
	clocks = <&clk_i2c5>, <&ext_26m>,
		<&clk_ap_apb_gates 13>;
};

&i2c6 {
	clocks = <&clk_aon_i2c>, <&ext_26m>,
		<&clk_aon_apb_gates0 31>;
};

&spi0 {
	clocks = <&clk_spi0>,<&ext_26m>,
		<&clk_ap_apb_gates 5>;
};

&spi1 {
	clocks = <&clk_spi1>,<&ext_26m>,
		<&clk_ap_apb_gates 6>;
};

&spi2 {
	clocks = <&clk_ap_hs_spi>,<&ext_26m>,
		<&clk_ap_apb_gates 7>,
		<&clk_aon_apb_gates0 21>;
};

&spi3 {
	clocks = <&clk_spi3>,<&ext_26m>,
		<&clk_ap_apb_gates 20>;
};

&hwslock1 {
	clocks = <&clk_aon_apb_gates0 22>;
};

&pin_controller {
	pinctrl-names = "pins-shutdown";
	pinctrl-0 = <&power_off>;
	power_off: poc {
		pins = <SC9861_RFCTL31_MISC 0x142001>,
		       <SC9861_U3CTS_MISC 0x14208a>,
		       <SC9861_CMPD1_MISC 0x142001>;
	};

	vio_sd0_ms_0: regctrl0 {
		pins = <SC9861_VSD_MS 0x0>;
	};

	vio_sd0_ms_1: regctrl1 {
		pins = <SC9861_VSD_MS 0x1>;
	};

	/* sys iis0 */
	vbc_iis0_0:reg3-iis0-c {
		pins = <SC9861_IIS0_SYS_SEL 0xc>;
	};

	vbc_iis1_0:reg3-iis0-d {
		pins = <SC9861_IIS0_SYS_SEL 0xd>;
	};

	vbc_iis2_0:reg3-iis0-e {
		pins = <SC9861_IIS0_SYS_SEL 0xe>;
	};

	vbc_iis3_0:reg3-iis0-f {
		pins = <SC9861_IIS0_SYS_SEL 0xf>;
	};

	/* sys iis2 */
	vbc_iis0_2:reg3-iis2-c {
		pins = <SC9861_IIS2_SYS_SEL 0xc>;
	};

	vbc_iis1_2:reg3-iis2-d {
		pins = <SC9861_IIS2_SYS_SEL 0xd>;
	};

	vbc_iis2_2:reg3-iis2-e {
		pins = <SC9861_IIS2_SYS_SEL 0xe>;
	};
	vbc_iis3_2:reg3-iis2-f {
		pins = <SC9861_IIS2_SYS_SEL 0xf>;
	};

	/* sys iis3 */
	vbc_iis0_3:reg4-iis3-c {
		pins = <SC9861_IIS3_SYS_SEL 0xc>;
	};

	vbc_iis1_3:reg4-iis3-d {
		pins = <SC9861_IIS3_SYS_SEL 0xd>;
	};

	vbc_iis2_3:reg4-iis3-e {
		pins = <SC9861_IIS3_SYS_SEL 0xe>;
	};

	vbc_iis3_3:reg4-iis3-f {
		pins = <SC9861_IIS3_SYS_SEL 0xf>;
	};

	/* typec for usb3.0 channel switch */
	gio_ldo_pin_sw: reg-pin-ctrl0 {
		pins = <SC9861_RF_LVDS1_ADC_ON 0x3>;
	};

	gio_ldo_ctl_md: reg-pin-ctrl1 {
		pins = <SC9861_RF_LVDS1_ADC_ON_MISC 0x156085>;
	};
};
